CM_ "AUTOGENERATED FILE, DO NOT EDIT";

CM_ "Imported file _stellantis_common_ram_dt_generated.dbc starts here";
CM_ "Generated from _stellantis_common.dbc";

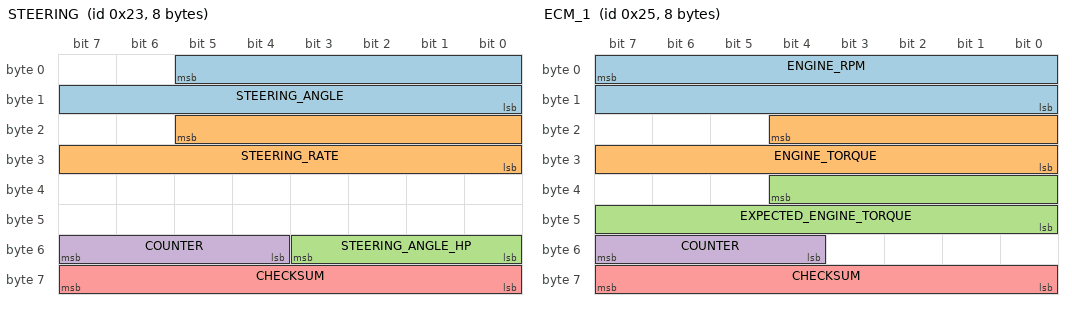
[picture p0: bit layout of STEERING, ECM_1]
BO_ 35 STEERING: 8 XXX
 SG_ STEERING_ANGLE : 5|14@0+ (0.5,-2048) [-2048|2047] "deg" XXX
 SG_ STEERING_RATE : 21|14@0+ (0.5,-2048) [-2048|2047] "deg/s" XXX
 SG_ STEERING_ANGLE_HP : 48|4@1+ (0.1,-0.4) [-0.4|0.4] "deg" XXX
 SG_ COUNTER : 55|4@0+ (1,0) [0|15] "" XXX
 SG_ CHECKSUM : 63|8@0+ (1,0) [0|255] "" XXX

BO_ 37 ECM_1: 8 XXX
 SG_ ENGINE_RPM : 7|16@0+ (1,0) [0|65535] "" XXX
 SG_ ENGINE_TORQUE : 20|13@0+ (0.25,-500) [-500|1547.5] "Nm" XXX
 SG_ EXPECTED_ENGINE_TORQUE : 36|13@0+ (0.25,-500) [-500|1547.5] "Nm" XXX
 SG_ COUNTER : 55|4@0+ (1,0) [0|15] "" XXX
 SG_ CHECKSUM : 63|8@0+ (1,0) [0|255] "" XXX

BO_ 181 ECM_TRQ: 8 XXX
 SG_ ENGINE_TORQ_MAX : 4|13@0+ (0.25,-500) [-500|1547.5] "NM" XXX
 SG_ ENGINE_TORQ_MIN : 20|13@0+ (0.25,-500) [-500|1547.5] "NM" XXX

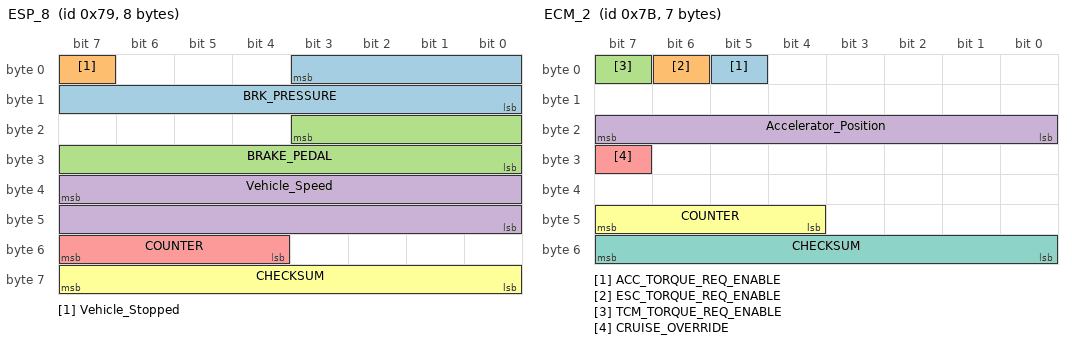
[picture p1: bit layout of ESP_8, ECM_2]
BO_ 121 ESP_8: 8 XXX
 SG_ BRK_PRESSURE : 3|12@0+ (1,0) [0|1] "" XXX
 SG_ Vehicle_Stopped : 7|1@0+ (1,0) [0|1] "" XXX
 SG_ BRAKE_PEDAL : 19|12@0+ (1,0) [0|1] "" XXX
 SG_ Vehicle_Speed : 39|16@0+ (0.0078125,0) [0|511.984375] "km/h" XXX
 SG_ COUNTER : 55|4@0+ (1,0) [0|15] "" XXX
 SG_ CHECKSUM : 63|8@0+ (1,0) [0|255] "" XXX

BO_ 123 ECM_2: 7 XXX
 SG_ ACC_TORQUE_REQ_ENABLE : 5|1@1+ (1,0) [0|0] "" XXX
 SG_ ESC_TORQUE_REQ_ENABLE : 6|1@1+ (1,0) [0|0] "" XXX
 SG_ TCM_TORQUE_REQ_ENABLE : 7|1@1+ (1,0) [0|0] "" XXX
 SG_ Accelerator_Position : 16|8@1+ (0.4,0) [0|100] "%" XXX
 SG_ CRUISE_OVERRIDE : 31|1@1+ (1,0) [0|0] "" XXX
 SG_ COUNTER : 47|4@0+ (1,0) [0|15] "" XXX
 SG_ CHECKSUM : 55|8@0+ (1,0) [0|0] "" XXX

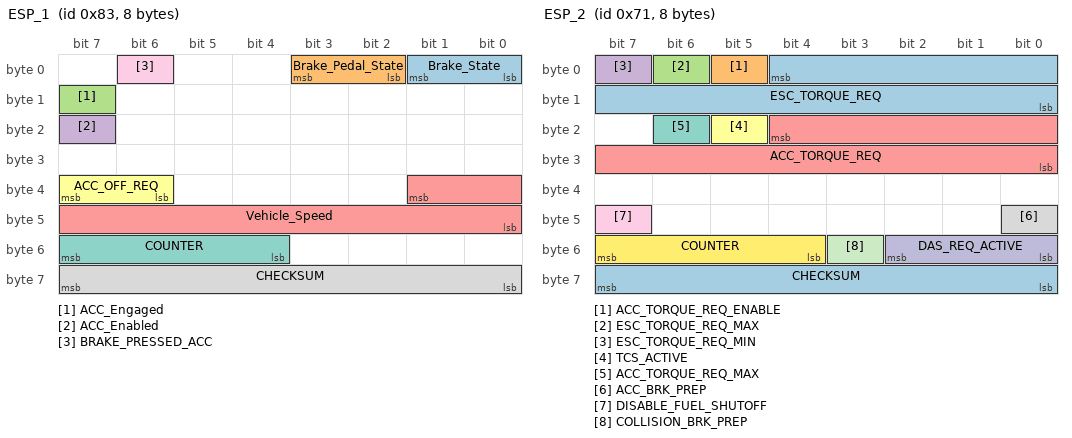
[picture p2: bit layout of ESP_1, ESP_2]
BO_ 131 ESP_1: 8 XXX
 SG_ Brake_State : 0|2@1+ (1,0) [0|0] "" XXX
 SG_ Brake_Pedal_State : 2|2@1+ (1,0) [0|0] "" XXX
 SG_ ACC_Engaged : 15|1@0+ (1,0) [0|1] "" XXX
 SG_ ACC_Enabled : 23|1@0+ (1,0) [0|1] "" XXX
 SG_ Vehicle_Speed : 33|10@0+ (0.5,0) [0|511] "km/h" XXX
 SG_ ACC_OFF_REQ : 39|2@0+ (1,0) [0|0] "" XXX
 SG_ COUNTER : 55|4@0+ (1,0) [0|15] "" XXX
 SG_ CHECKSUM : 63|8@0+ (1,0) [0|255] "" XXX
 SG_ BRAKE_PRESSED_ACC : 6|1@0+ (1,0) [0|3] "" XXX

BO_ 113 ESP_2: 8 ESC
 SG_ ESC_TORQUE_REQ : 4|13@0+ (0.25,-500) [-500|1547.5] "Nm" XXX
 SG_ ACC_TORQUE_REQ_ENABLE : 5|1@1+ (1,0) [0|0] "" XXX
 SG_ ESC_TORQUE_REQ_MAX : 6|1@1+ (1,0) [0|0] "" XXX
 SG_ ESC_TORQUE_REQ_MIN : 7|1@1+ (1,0) [0|0] "" XXX
 SG_ ACC_TORQUE_REQ : 20|13@0+ (0.25,-500) [-500|1547.5] "Nm" XXX
 SG_ TCS_ACTIVE : 21|1@1+ (1,0) [0|0] "" XXX
 SG_ ACC_TORQUE_REQ_MAX : 22|1@1+ (1,0) [0|0] "" XXX
 SG_ ACC_BRK_PREP : 40|1@1+ (1,0) [0|0] "" XXX
 SG_ DISABLE_FUEL_SHUTOFF : 47|1@1+ (1,0) [0|0] "" XXX
 SG_ DAS_REQ_ACTIVE : 48|3@1+ (1,0) [0|0] "" XXX
 SG_ COLLISION_BRK_PREP : 51|1@1+ (1,0) [0|0] "" XXX
 SG_ COUNTER : 55|4@0+ (1,0) [0|15] "" XXX
 SG_ CHECKSUM : 63|8@0+ (1,0) [0|0] "" XXX

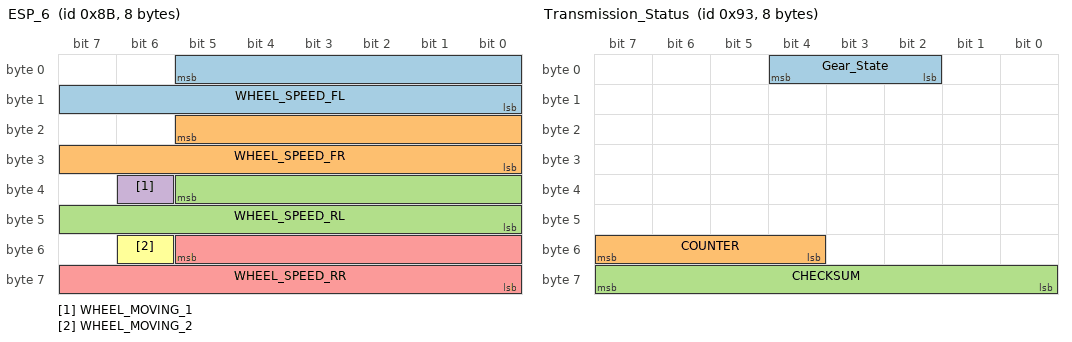
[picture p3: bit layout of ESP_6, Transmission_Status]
BO_ 139 ESP_6: 8 XXX
 SG_ WHEEL_SPEED_FL : 5|14@0+ (0.5,0) [0|8191] "rpm" XXX
 SG_ WHEEL_SPEED_FR : 21|14@0+ (0.5,0) [0|8191] "rpm" XXX
 SG_ WHEEL_SPEED_RL : 37|14@0+ (0.5,0) [0|8191] "rpm" XXX
 SG_ WHEEL_MOVING_1 : 38|1@0+ (1,0) [0|1] "" XXX
 SG_ WHEEL_SPEED_RR : 53|14@0+ (0.5,0) [0|8191] "rpm" XXX
 SG_ WHEEL_MOVING_2 : 54|1@0+ (1,0) [0|1] "" XXX

BO_ 147 Transmission_Status: 8 XXX
 SG_ Gear_State : 2|3@1+ (1,0) [0|15] "" XXX
 SG_ COUNTER : 55|4@0+ (1,0) [0|15] "" XXX
 SG_ CHECKSUM : 63|8@0+ (1,0) [0|255] "" XXX

BO_ 464 ORC_1: 8 XXX
 SG_ SEATBELT_DRIVER_UNLATCHED : 13|1@0+ (1,0) [0|1] "" XXX

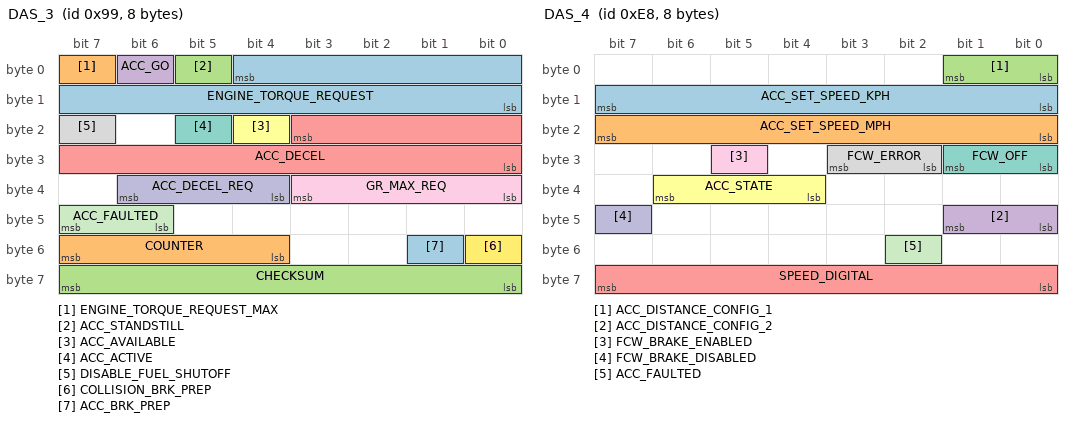
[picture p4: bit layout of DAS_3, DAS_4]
BO_ 153 DAS_3: 8 XXX
 SG_ ENGINE_TORQUE_REQUEST : 4|13@0+ (0.25,-500) [-500|1547.5] "Nm" XXX
 SG_ ENGINE_TORQUE_REQUEST_MAX : 7|1@0+ (1,0) [0|1] "" XXX
 SG_ ACC_STANDSTILL : 5|1@0+ (1,0) [0|1] ""  XXX
 SG_ ACC_GO : 6|1@1+ (1,0) [0|0] "" XXX
 SG_ ACC_DECEL : 19|12@0+ (0.004885,-16) [-16|4] "m/s2" XXX
 SG_ ACC_AVAILABLE : 20|1@0+ (1,0) [0|1] "" XXX
 SG_ ACC_ACTIVE : 21|1@0+ (1,0) [0|1] "" XXX
 SG_ DISABLE_FUEL_SHUTOFF : 23|1@1+ (1,0) [0|0] "" XXX
 SG_ GR_MAX_REQ : 32|4@1+ (1,0) [0|0] "" XXX
 SG_ ACC_DECEL_REQ : 36|3@1+ (1,0) [0|0] "" XXX
 SG_ ACC_FAULTED : 46|2@1+ (1,0) [0|0] "" XXX
 SG_ COLLISION_BRK_PREP : 48|1@1+ (1,0) [0|0] "" XXX
 SG_ ACC_BRK_PREP : 49|1@1+ (1,0) [0|0] "" XXX
 SG_ COUNTER : 55|4@0+ (1,0) [0|15] "" XXX
 SG_ CHECKSUM : 63|8@0+ (1,0) [0|255] "" XXX

BO_ 232 DAS_4: 8 XXX
 SG_ ACC_SET_SPEED_KPH : 15|8@0+ (1,0) [0|3] "km/h" XXX
 SG_ ACC_SET_SPEED_MPH : 23|8@0+ (1,0) [0|3] "mph" XXX
 SG_ ACC_DISTANCE_CONFIG_1 : 1|2@0+ (1,0) [0|3] "" XXX
 SG_ ACC_DISTANCE_CONFIG_2 : 41|2@0+ (1,0) [0|3] "" XXX
 SG_ SPEED_DIGITAL : 63|8@0+ (1,0) [0|255] "mph" XXX
 SG_ ACC_STATE : 38|3@0+ (1,0) [0|7] "" XXX
 SG_ FCW_OFF : 25|2@0+ (1,0) [0|3] "" XXX
 SG_ FCW_ERROR : 27|2@0+ (1,0) [0|3] "" XXX
 SG_ FCW_BRAKE_ENABLED : 29|1@0+ (1,0) [0|1] "" XXX
 SG_ FCW_BRAKE_DISABLED : 47|1@0+ (1,0) [0|1] "" XXX
 SG_ ACC_FAULTED : 50|1@0+ (1,0) [0|1] "" XXX

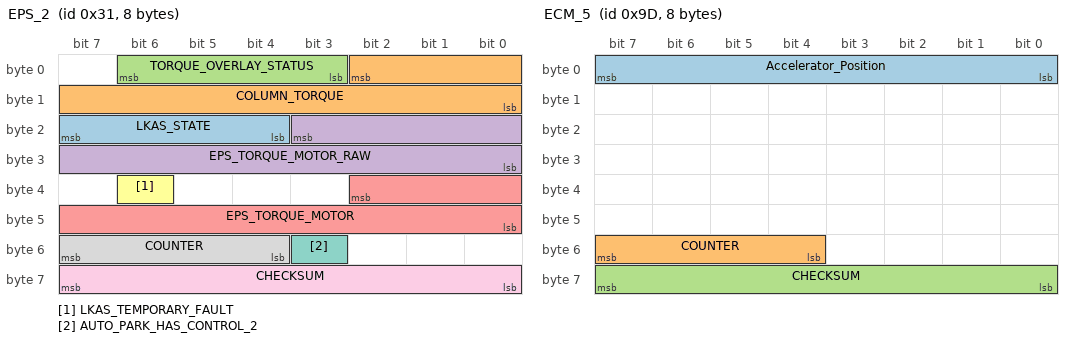
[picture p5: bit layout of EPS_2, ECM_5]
BO_ 49 EPS_2: 8 XXX
 SG_ LKAS_STATE : 23|4@0+ (1,0) [0|15] "" XXX
 SG_ COLUMN_TORQUE : 2|11@0+ (1,-1024) [-1024|1023] "" XXX
 SG_ TORQUE_OVERLAY_STATUS : 6|4@0+ (1,0) [0|15] "" XXX
 SG_ EPS_TORQUE_MOTOR_RAW : 19|12@0+ (1,-2048) [-2048|2047] "" XXX
 SG_ EPS_TORQUE_MOTOR : 34|11@0+ (1,-1024) [-1024|1023] "" XXX
 SG_ LKAS_TEMPORARY_FAULT : 38|1@0+ (1,0) [0|1] "" XXX
 SG_ AUTO_PARK_HAS_CONTROL_2 : 51|1@0+ (1,0) [0|1] "" XXX
 SG_ COUNTER : 55|4@0+ (1,0) [0|15] "" XXX
 SG_ CHECKSUM : 63|8@0+ (1,0) [0|255] "" XXX

BO_ 157 ECM_5: 8 XXX
 SG_ Accelerator_Position : 0|8@1+ (0.4,0) [0|100] "%" XXX
 SG_ COUNTER : 55|4@0+ (1,0) [0|15] "" XXX
 SG_ CHECKSUM : 63|8@0+ (1,0) [0|255] "" XXX

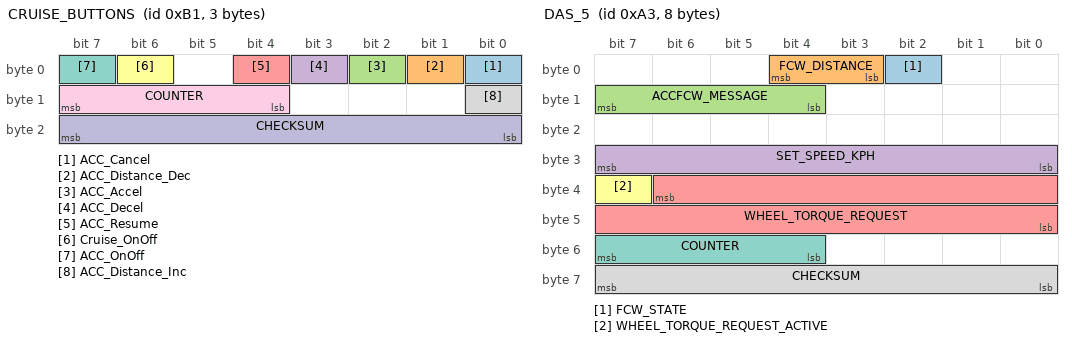
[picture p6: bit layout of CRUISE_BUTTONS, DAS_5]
BO_ 177 CRUISE_BUTTONS: 3 XXX
 SG_ ACC_Cancel : 0|1@1+ (1,0) [0|0] "" XXX
 SG_ ACC_Distance_Dec : 1|1@1+ (1,0) [0|0] "" XXX
 SG_ ACC_Accel : 2|1@1+ (1,0) [0|0] "" XXX
 SG_ ACC_Decel : 3|1@1+ (1,0) [0|0] "" XXX
 SG_ ACC_Resume : 4|1@0+ (1,0) [0|1] "" XXX
 SG_ Cruise_OnOff : 6|1@1+ (1,0) [0|0] "" XXX
 SG_ ACC_OnOff : 7|1@1+ (1,0) [0|0] "" XXX
 SG_ ACC_Distance_Inc : 8|1@1+ (1,0) [0|0] "" XXX
 SG_ COUNTER : 15|4@0+ (1,0) [0|15] "" XXX
 SG_ CHECKSUM : 23|8@0+ (1,0) [0|255] "" XXX

BO_ 163 DAS_5: 8 XXX
 SG_ FCW_STATE : 2|1@1+ (1,0) [0|0] ""  XXX
 SG_ FCW_DISTANCE : 3|2@1+ (1,0) [0|0] ""  XXX
 SG_ ACCFCW_MESSAGE : 12|4@1+ (1,0) [0|0] ""  XXX
 SG_ SET_SPEED_KPH : 24|8@1+ (1,0) [0|250] "km/h"  XXX
 SG_ WHEEL_TORQUE_REQUEST : 38|15@0+ (1,-7767) [-7767|24999] "Nm"  XXX
 SG_ WHEEL_TORQUE_REQUEST_ACTIVE : 39|1@1+ (1,0) [0|0] ""  XXX
 SG_ COUNTER : 55|4@0+ (1,0) [0|15] "" XXX
 SG_ CHECKSUM : 63|8@0+ (1,0) [0|255] "" XXX

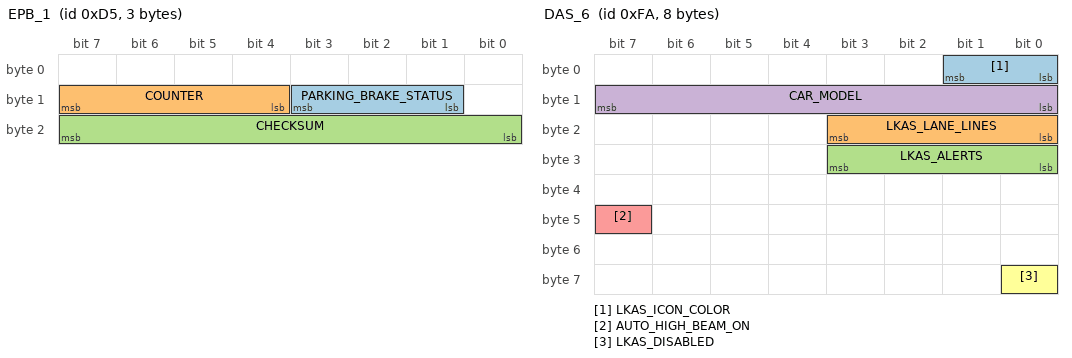
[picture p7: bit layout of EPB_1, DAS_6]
BO_ 213 EPB_1: 3 XXX
 SG_ PARKING_BRAKE_STATUS : 11|3@0+ (1,0) [0|7] "" XXX
 SG_ COUNTER : 15|4@0+ (1,0) [0|15] "" XXX
 SG_ CHECKSUM : 23|8@0+ (1,0) [0|255] "" XXX

BO_ 250 DAS_6: 8 XXX
 SG_ LKAS_ICON_COLOR : 1|2@0+ (1,0) [0|3] "" XXX
 SG_ LKAS_LANE_LINES : 19|4@0+ (1,0) [0|1] "" XXX
 SG_ LKAS_ALERTS : 27|4@0+ (1,0) [0|1] "" XXX
 SG_ CAR_MODEL : 15|8@0+ (1,0) [0|255] "" XXX
 SG_ AUTO_HIGH_BEAM_ON : 47|1@1+ (1,0) [0|0] "" XXX
 SG_ LKAS_DISABLED : 56|1@1+ (1,0) [0|0] "" XXX

BO_ 720 BSM_1: 6 XXX
 SG_ RIGHT_STATUS : 5|1@0+ (1,0) [0|1] "" XXX
 SG_ LEFT_STATUS : 2|1@0+ (1,0) [0|1] "" XXX

BO_ 792 STEERING_LEVERS: 8 XXX
 SG_ TURN_SIGNALS : 0|2@1+ (1,0) [0|3] "" XXX
 SG_ HIGH_BEAM_PRESSED : 2|1@0+ (1,0) [0|3] "" XXX

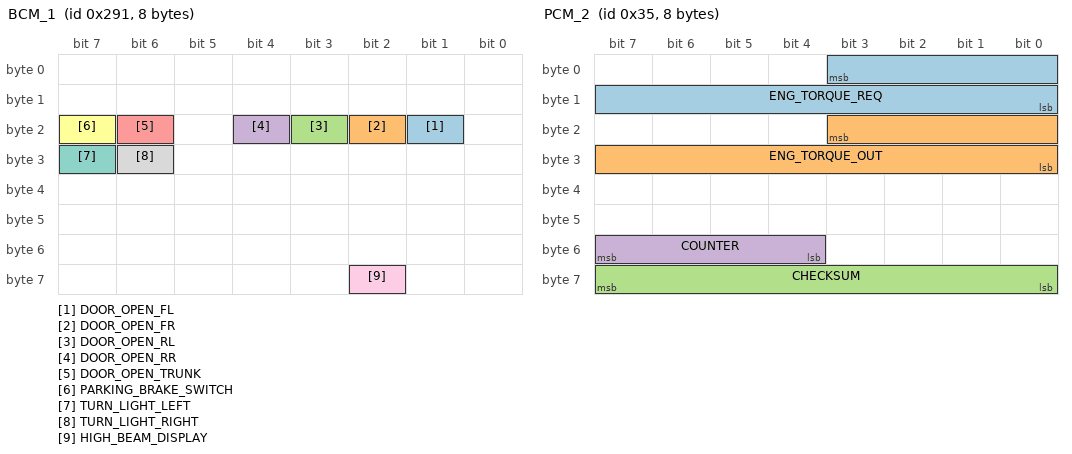
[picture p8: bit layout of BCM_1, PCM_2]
BO_ 657 BCM_1: 8 XXX
 SG_ DOOR_OPEN_FL : 17|1@0+ (1,0) [0|1] "" XXX
 SG_ DOOR_OPEN_FR : 18|1@0+ (1,0) [0|1] "" XXX
 SG_ DOOR_OPEN_RL : 19|1@0+ (1,0) [0|1] "" XXX
 SG_ DOOR_OPEN_RR : 20|1@0+ (1,0) [0|1] "" XXX
 SG_ DOOR_OPEN_TRUNK : 22|1@0+ (1,0) [0|1] "" XXX
 SG_ PARKING_BRAKE_SWITCH : 23|1@0+ (1,0) [0|1] "" XXX
 SG_ TURN_LIGHT_LEFT : 31|1@0+ (1,0) [0|1] "" XXX
 SG_ TURN_LIGHT_RIGHT : 30|1@0+ (1,0) [0|1] "" XXX
 SG_ HIGH_BEAM_DISPLAY : 58|1@0+ (1,0) [0|1] "" XXX

VAL_ 131 ACC_OFF_REQ 2 "PERMANENT" 1 "TEMPORARY" 0 "NONE" ;
VAL_ 147 Gear_State 4 "D" 2 "N" 1 "R" 0 "P" ;
VAL_ 213 PARKING_BRAKE_STATUS 3 "RELEASING" 2 "APPLYING" 1 "APPLIED" 0 "OFF" ;

CM_ SG_ 258 STEERING_ANGLE_HP "Steering angle high precision";
CM_ SG_ 264 ENGINE_TORQUE "Effective engine torque";
CM_ SG_ 264 EXPECTED_ENGINE_TORQUE "Expected Engine Torque based on target engine speed";
CM_ SG_ 678 LKAS_ICON_COLOR "3 is yellow, 2 is green, 1 is white, 0 is null";
CM_ SG_ 678 LKAS_LANE_LINES "0x01 transparent lines, 0x02 left white, 0x03 right white, 0x04 left yellow with car on top, 0x05 left yellow with car on top, 0x06 both white, 0x07 left yellow, 0x08 left yellow right white, 0x09 right yellow, 0x0a right yellow left white, 0x0b left yellow with car on top right white, 0x0c right yellow with car on top left white, (0x00, 0x0d, 0x0e, 0x0f) null";
CM_ SG_ 678 LKAS_ALERTS "(0x01, 0x02) lane sense off, (0x03, 0x04, 0x06) place hands on steering wheel, 0x07 lane departure detected + place hands on steering wheel, (0x08, 0x09) lane sense unavailable + clean front windshield, 0x0b lane sense and auto high beam unavailable + clean front windshield, 0x0c lane sense unavailable + service required, (0x00, 0x05, 0x0a, 0x0d, 0x0e, 0x0f) null";

CM_ "chrysler_ram_dt.dbc starts here";

BO_ 53 PCM_2: 8 XXX
 SG_ ENG_TORQUE_REQ : 3|12@0+ (1,0) [0|7] "" XXX
 SG_ ENG_TORQUE_OUT : 19|12@0+ (1,0) [0|1] "" XXX
 SG_ CHECKSUM : 63|8@0+ (1,0) [0|255] "" XXX
 SG_ COUNTER : 55|4@0+ (1,0) [0|15] "" XXX

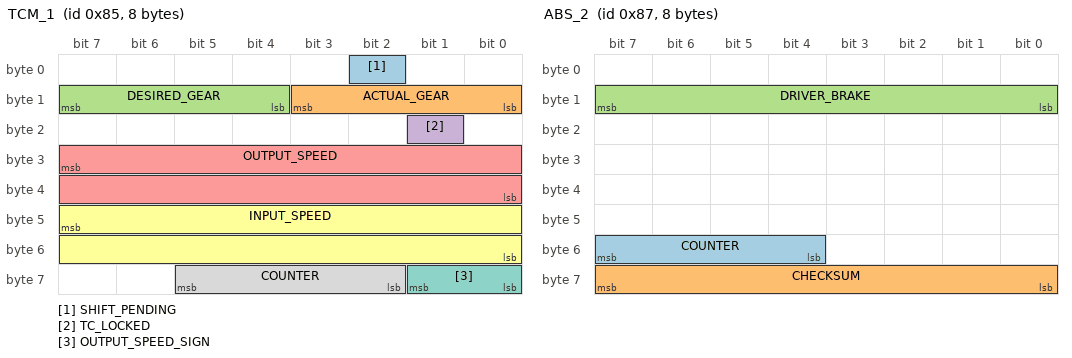
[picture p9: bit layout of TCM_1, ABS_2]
BO_ 133 TCM_1: 8 XXX
 SG_ SHIFT_PENDING : 2|1@0+ (1,0) [0|1] "" XXX
 SG_ ACTUAL_GEAR : 11|4@0+ (1,0) [0|15] "" XXX
 SG_ DESIRED_GEAR : 15|4@0+ (1,0) [0|1] "" XXX
 SG_ TC_LOCKED : 17|1@1+ (1,0) [0|0] ""  XXX
 SG_ OUTPUT_SPEED : 31|16@0+ (1,0) [0|65534] "rpm" XXX
 SG_ INPUT_SPEED : 47|16@0+ (1,0) [0|65534] "rpm"  XXX
 SG_ OUTPUT_SPEED_SIGN : 57|2@0+ (1,0) [0|3] "" XXX
 SG_ COUNTER : 61|4@0+ (1,0) [0|15] "" XXX

BO_ 135 ABS_2: 8 XXX
 SG_ COUNTER : 55|4@0+ (1,0) [0|1] "" XXX
 SG_ CHECKSUM : 63|8@0+ (1,0) [0|1] "" XXX
 SG_ DRIVER_BRAKE : 15|8@0+ (1,0) [0|1] "" XXX

BO_ 137 ESP_4: 8 XXX
 SG_ Yaw_Rate : 7|16@0+ (0.01,-327.68) [-327.68|327.66] "deg/s" XXX
 SG_ Acceleration : 32|8@1+ (0.08,-10.24) [-10.24|10.08] "m/s2" XXX

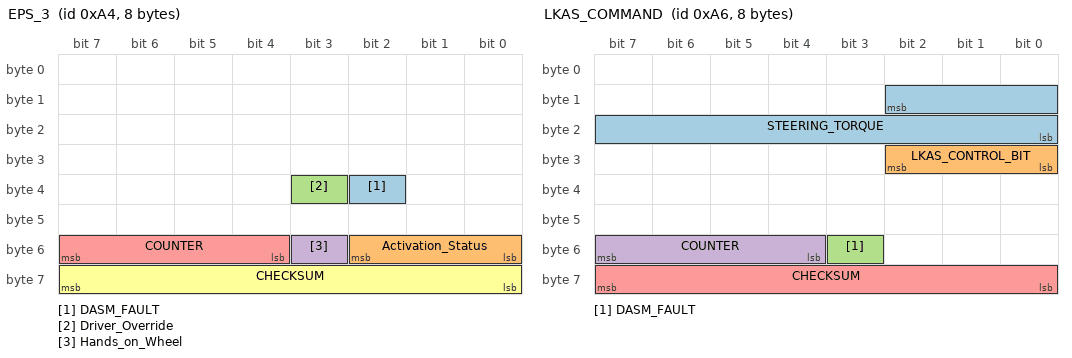
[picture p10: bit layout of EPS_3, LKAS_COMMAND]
BO_ 164 EPS_3: 8 XXX
 SG_ DASM_FAULT : 34|1@0+ (1,0) [0|1] "" XXX
 SG_ Activation_Status : 48|3@1+ (1,0) [0|1] "" XXX
 SG_ Driver_Override : 35|1@0+ (1,0) [0|1] "" XXX
 SG_ Hands_on_Wheel : 51|1@0+ (1,0) [0|1] "" XXX
 SG_ COUNTER : 55|4@0+ (1,0) [0|15] "" XXX
 SG_ CHECKSUM : 63|8@0+ (1,0) [0|255] "" XXX

BO_ 166 LKAS_COMMAND: 8 XXX
 SG_ STEERING_TORQUE : 10|11@0+ (1,-1024) [0|1] "" XXX
 SG_ LKAS_CONTROL_BIT : 24|3@1+ (1,0) [0|1] "" XXX
 SG_ DASM_FAULT : 51|1@0+ (1,0) [0|1] "" XXX
 SG_ COUNTER : 55|4@0+ (1,0) [0|15] "" XXX
 SG_ CHECKSUM : 63|8@0+ (1,0) [0|255] "" XXX

BO_ 221 Center_Stack_1: 8 XXX
 SG_ LKAS_Button : 53|1@1+ (1,0) [0|0] "" XXX
 SG_ Traction_Button : 54|1@0+ (1,0) [0|1] "" XXX

BO_ 650 Center_Stack_2: 8 XXX
 SG_ LKAS_Button : 57|1@1+ (1,0) [0|0] "" XXX

CM_ SG_ 133 ACTUAL_GEAR "0xd = P, 0x1-8 = D (actual gear), 0xb = R or N?? TODO find R vs N";
CM_ SG_ 153 ACC_Engaged "SENT BY FORWARD CAMERA 1 = ACTIVE, 3 = ENGAGED, 0 = DISENGAGED/OFF";
CM_ SG_ 166 LKAS_CONTROL_BIT "0=IDLE, 1=HAS 2=LKAS 3=ABSD, 4=TJA, 7=SNA";
CM_ SG_ 250 Auto_High_Beam "1 = HIGH BEAMS OK 0 = HIGH BEAMS OFF ";
CM_ SG_ 250 LKAS_LANE_LINES "9 = LEFT CAUTION, 11 = VERY LEFT CAUTION 10 = RIGHT CAUTION, 14 = VERY RIGHT, 4 = NO LINES DETECTED, 3 = LINES DETECTED, SYSTEM ACTIVE";
CM_ SG_ 464 Driver_Seatbelt_Status "1 unbuckled 0 buckled";
CM_ SG_ 792 High_Beam_Lever_Status "1 is high beam, 0 reg";
